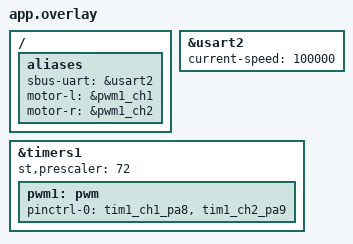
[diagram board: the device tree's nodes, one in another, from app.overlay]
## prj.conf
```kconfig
CONFIG_GPIO=y
CONFIG_PWM=y
CONFIG_SERIAL=y
CONFIG_UART_INTERRUPT_DRIVEN=y
```

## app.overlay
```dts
/ {
    /* Define aliases for easy access in C code */
    aliases {
        sbus-uart = &usart2;
        motor-l = &pwm1_ch1;
        motor-r = &pwm1_ch2;
    };
};

&usart2 {
    status = "okay";
    current-speed = <100000>;
    /* Note: F103 lacks hardware inversion; use external inverter */
};

&timers1 {
    status = "okay";
    st,prescaler = <72>; /* 1MHz clock if CPU is 72MHz */
    pwm1: pwm {
        status = "okay";
        pinctrl-0 = <&tim1_ch1_pa8 &tim1_ch2_pa9>;
        pinctrl-names = "default";
    };
};
```

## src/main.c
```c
#include <zephyr/kernel.h>
#include <zephyr/device.h>
#include <zephyr/drivers/pwm.h>
#include <zephyr/logging/log.h>

LOG_MODULE_REGISTER(diff_drive, LOG_LEVEL_INF);

/* Devicetree node identifiers */
#define PWM_LEFT_NODE  DT_ALIAS(pwm_left)
#define PWM_RIGHT_NODE DT_ALIAS(pwm_right)

#if !DT_NODE_HAS_STATUS(PWM_LEFT_NODE, okay) || !DT_NODE_HAS_STATUS(PWM_RIGHT_NODE, okay)
#error "Unsupported board: PWM devicetree aliases not defined"
#endif

static const struct pwm_dt_spec pwm_left = PWM_DT_SPEC_GET(PWM_LEFT_NODE);
static const struct pwm_dt_spec pwm_right = PWM_DT_SPEC_GET(PWM_RIGHT_NODE);

/* PWM period in nanoseconds (e.g., 20kHz = 50000ns) */
#define PWM_PERIOD_NS  50000

/* Differential Control Function */
void set_motors(int32_t left_speed, int32_t right_speed)
{
    // Clamp speeds between 0 and 100
    left_speed = CLAMP(left_speed, 0, 100);
    right_speed = CLAMP(right_speed, 0, 100);

    // Convert % to duty cycle (assuming duty_cycle = period * % / 100)
    uint32_t left_dc = (PWM_PERIOD_NS * left_speed) / 100;
    uint32_t right_dc = (PWM_PERIOD_NS * right_speed) / 100;

    pwm_set_dt(&pwm_left, PWM_PERIOD_NS, left_dc);
    pwm_set_dt(&pwm_right, PWM_PERIOD_NS, right_dc);
}

int main(void)
{
    int ret;

    LOG_INF("Differential Drive Controller Starting");

    if (!pwm_is_ready_dt(&pwm_left) || !pwm_is_ready_dt(&pwm_right)) {
        LOG_ERR("PWM devices not ready");
        return -1;
    }

    // Example driving loop: Move forward then turn
    while (1) {
        LOG_INF("Forward");
        set_motors(70, 70); // 70% speed
        k_sleep(K_SECONDS(2));

        LOG_INF("Turn Right");
        set_motors(60, 20); // Differential speed
        k_sleep(K_SECONDS(2));

        LOG_INF("Stop");
        set_motors(0, 0);
        k_sleep(K_SECONDS(1));
    }
    return 0;
}
```

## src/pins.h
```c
#ifndef PINS_H
#define PINS_H

// STM32 BluePill Pin Definitions
// Using pin numbers that correspond to STM32F103C8T6

// Receiver Input Pins
#define S_BUS_IN PA10  // Serial1 RX pin for SBUS

// IBT_2 Motor Driver Pins (Left Motor) - JST near PB4-PB9
#define LRPWM PA1     // PWM-capable pin (Timer 4, Channel 1)
#define LLPWM PA0     // PWM-capable pin (Timer 4, Channel 2)
#define LEN PB5       // Digital pin (Enable)
#define LR_IS PB0     // Analog pin for right current sensing
#define LL_IS PB1     // Analog pin for left current sensing

// IBT_2 Motor Driver Pins (Right Motor) - JST near PA7-PC13
#define RRPWM PA6     // PWM-capable pin (Timer 3, Channel 2)
#define RLPWM PA7     // PWM-capable pin (Timer 3, Channel 3)
#define REN PA4       // Digital pin (Enable)
#define RR_IS PA3     // Analog pin for right current sensing
#define RL_IS PA2     // Analog pin for left current sensing

// Weapon Motor ESC Pin (ESC only needs one PWM signal)
#define WEAPON_ESC_PIN PB6     // PWM signal to Weapon Motor ESC

// Buzzer Pin
#define BUZZER_PIN PB12  // PWM-capable pin for buzzer/beeper

// RGB LED Pins
#define RGB_RED_PIN   PB13   // PWM-capable pin for Red
#define RGB_GREEN_PIN PB14   // PWM-capable pin for Green  
#define RGB_BLUE_PIN  PB15   // PWM-capable pin for Blue

// Built-in LED for status indication
#define LED_PIN PC13  // Built-in LED on BluePill

// Serial pins for debugging
#define RX_PIN PB11
#define TX_PIN PB10

// ESC Configuration (for weapon motor only)
#define ESC_MIN_PULSE 1000     // Minimum pulse width (microseconds) - full reverse
#define ESC_NEUTRAL_PULSE 1500 // Neutral pulse width (microseconds) - stop
#define ESC_MAX_PULSE 2000     // Maximum pulse width (microseconds) - full forward

#define NOISE_THRESHOLD 15    // Ignore small values < 15 in PWM

#define THROTTLE_CHANNEL 1
#define STEERING_CHANNEL 0
#define WEAPON_CHANNEL 2
#define KILL_SWITCH_CHANNEL 5 // Channel 6 (zero-based index)
#define WEAPON_STATE_CHANNEL 6 // Channel 7
#define STEERING_INVERT_CHANNEL 7 // Channel 8

#define TIMEOUT_MS 500        // Stop bot if no SBUS data received in 500ms

#endif // PINS_H
```
